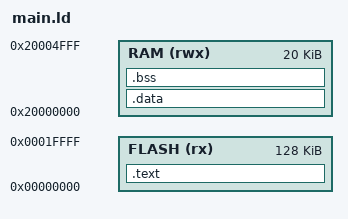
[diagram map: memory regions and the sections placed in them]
ENTRY(main)
MEMORY
{
  FLASH (rx) : ORIGIN = 0x00000000, LENGTH = 128K
  RAM (rwx) : ORIGIN = 0x20000000, LENGTH = 20K

}

SECTIONS
{
	.text :
	{
		KEEP(*(.isr_vector))
 		*(.text)
 		*(.text.*)
		*(.rodata)
		*(.rodata.*)
		_sidata = .;
	} >FLASH

	/* Initialized data will initially be loaded in FLASH at the end of the .text section. */
    .data : AT (_sidata)  
    {
		_sdata = .;
		*(.data)		/* Initialized data */
		_edata = .;
	} >RAM
	. = ALIGN(4);
	.bss :
    {
    /* This is used by the startup in order to initialize the .bss secion */
    _sbss = .;         /* define a global symbol at bss start */
    __bss_start__ = _sbss;
    *(.bss)
    *(.bss*)
    *(COMMON)

    . = ALIGN(4);
    _ebss = .;         /* define a global symbol at bss end */
    __bss_end__ = _ebss;
    } >RAM

    
    _estack = ORIGIN(RAM) + LENGTH(RAM);
 }  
